AUTOSAR XML (schema 4-0-3)
package /ComponentTypes
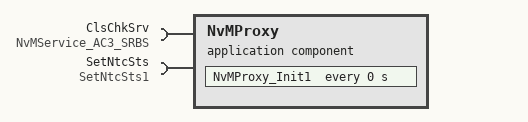
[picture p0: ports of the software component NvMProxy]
  application sw component type NvMProxy
    require port ClsChkSrv: required-interface=NvMService_AC3_SRBS
    require port SetNtcSts: required-interface=SetNtcSts1
    behavior NvMProxy_InternalBehavior: data-type-mapping=Nexteer
      ar-typed-per-instance-memorys:
        data NvMProxyClsChkBlk: sw-calibration-access=READ-ONLY, type=Cnt15
        data NvMProxyFltTbl: sw-calibration-access=READ-ONLY, type=NvMProxyFltTblApplAry1D1
        data NvMProxyRtnBuf: sw-calibration-access=READ-ONLY, type=NvMProxyRtnBufApplAry1D
      timing event NvMProxy_InitEvent: start-on-event=NvMProxy_Init1, period=0
      runnable NvMProxy_Init1
        sync call SC_SetNtcSts_Oper: operation=SetNtcSts.Oper, timeout=0
      swc service dependency ClsChkBlk: assigned-datas=role-based-data-assignment={role=ramBlock, used-data-element=NvMProxyClsChkBlk}
        assigned-ports:
          port-prototype=ClsChkSrv, role=NvMService_AC3_SRBS
          port-prototype=ClsChkSrv, role=NvMService_AC3_SRBS
        service-needs:
          nv block needs ClsChkSrv: n-data-sets=0, readonly=false, reliability=ERROR-DETECTION, resistant-to-changed-sw=true, restore-at-start=true, store-at-shutdown=true, write-only-once=false, writing-frequency=0, writing-priority=LOW
  swc implementation NvMProxy_Implementation: behavior=NvMProxy_InternalBehavior
    code-descriptors:
      code Default: artifact-descriptors=autosar-engineering-object={short-label=Default, category=SWSRC}
